# ATmega256RFR2 register map
Vendor: Atmel; File version: 1.0
CPU: other r0p0, little endian, no MPU, no FPU, 4 interrupt priority bits
Registers are 8-bit, read-write, reset 0x0 unless marked. A register's access mark holds for its fields unless they carry their own. Offsets are from the block's base; [hi:lo] are bit positions; {n}, {i} and the like mark numbered series.

## AC — Analog Comparator
Base 0x00000050
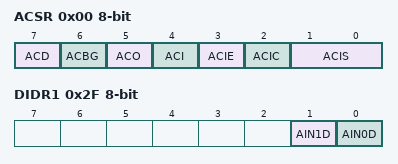
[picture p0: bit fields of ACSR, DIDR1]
0x00 ACSR — Analog Comparator Control And Status Register
  [7] ACD — Analog Comparator Disable
  [6] ACBG — Analog Comparator Bandgap Select
  [5] ACO — Analog Compare Output
  [4] ACI — Analog Comparator Interrupt Flag
  [3] ACIE — Analog Comparator Interrupt Enable
  [2] ACIC — Analog Comparator Input Capture Enable
  [1:0] ACIS — Analog Comparator Interrupt Mode Select
    0=Interrupt on Toggle; 2=Interrupt on Falling Edge; 3=Interrupt on Rising Edge
0x2B ADCSRB — ADC Control and Status Register B
  [6] ACME — Analog Comparator Multiplexer Enable
0x2F DIDR1 — Digital Input Disable Register 1
  [1] AIN1D — AIN1 Digital Input Disable
  [0] AIN0D — AIN0 Digital Input Disable

## ADC — Analog-to-Digital Converter
Base 0x00000077
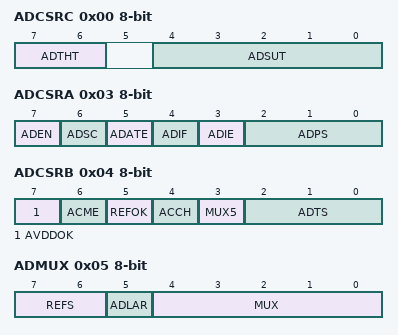
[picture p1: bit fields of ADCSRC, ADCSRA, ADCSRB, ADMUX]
0x00 ADCSRC — The ADC Control and Status Register C
  [7:6] ADTHT — ADC Track-and-Hold Time
    0=Single ended: 1, differential 3 ADC clock cycles; 1=Single ended: 2, differential 5 ADC clock cycles; 2=Single ended: 3, differential 7 ADC clock cycles; 3=Single ended: 4, differential 9 ADC clock cycles
  [4:0] ADSUT — ADC Start-up Time
    0=3 ADC clock cycles; 1=7 ADC clock cycles; 2=11 ADC clock cycles; 3=15 ADC clock cycles; 4=VAL_0x04
0x01 ADC 16-bit (reset mask 0xFF) — ADC Data Register Bytes
0x03 ADCSRA — The ADC Control and Status Register A
  [7] ADEN — ADC Enable
  [6] ADSC — ADC Start Conversion
  [5] ADATE — ADC Auto Trigger Enable
  [4] ADIF — ADC Interrupt Flag
  [3] ADIE — ADC Interrupt Enable
  [2:0] ADPS — ADC Prescaler Select Bits
    0=2; 1=2; 2=4; 3=8; 4=16; 5=32; 6=64; 7=128
0x04 ADCSRB — The ADC Control and Status Register B
  [7] AVDDOK — AVDD Supply Voltage OK
  [6] ACME — Analog Comparator Multiplexer Enable
  [5] REFOK — Reference Voltage OK
  [4] ACCH — Analog Channel Change
  [3] MUX5 — Analog Channel and Gain Selection Bits
  [2:0] ADTS — ADC Auto Trigger Source
    0=Free Running mode; 1=Analog Comparator; 2=External Interrupt Request 0; 3=Timer/Counter0 Compare Match A; 4=Timer/Counter0 Overflow; 5=Timer/Counter1 Compare Match B; 6=Timer/Counter1 Overflow; 7=Timer/Counter1 Capture Event
0x05 ADMUX — The ADC Multiplexer Selection Register
  [7:6] REFS — Reference Selection Bits
    0=AREF, Internal reference voltage generation turned off; 1=AVDD with external capacitor at AREF pin; 2=Internal 1.5V Voltage Reference (no external capacitor at AREF pin); 3=Internal 1.6V Voltage Reference (no external capacitor at AREF pin)
  [5] ADLAR — ADC Left Adjust Result
  [4:0] MUX — Analog Channel and Gain Selection Bits
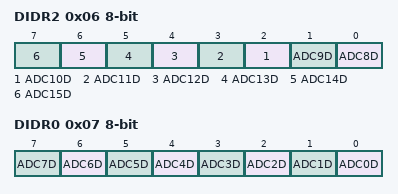
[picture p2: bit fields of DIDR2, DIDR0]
0x06 DIDR2 — Digital Input Disable Register 2
  [n-8] ADC{n}D (n=8..15) — Reserved Bits
0x07 DIDR0 — Digital Input Disable Register 0
  [n] ADC{n}D (n=0..7) — Disable ADC7:0 Digital Input

## BOOT_LOAD — Bootloader
Base 0x00000057
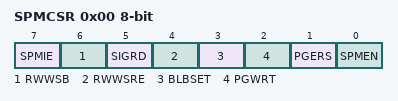
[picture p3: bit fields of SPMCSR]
0x00 SPMCSR — Store Program Memory Control Register
  [7] SPMIE — SPM Interrupt Enable
  [6] RWWSB — Read While Write Section Busy
  [5] SIGRD — Signature Row Read
  [4] RWWSRE — Read While Write Section Read Enable
  [3] BLBSET — Boot Lock Bit Set
  [2] PGWRT — Page Write
  [1] PGERS — Page Erase
  [0] SPMEN — Store Program Memory Enable

## CPU — CPU Registers
Base 0x0000003E
0x00 GPIOR0 — General Purpose IO Register 0
0x0C GPIOR1 — General Purpose IO Register 1
0x0D GPIOR2 — General Purpose I/O Register 2
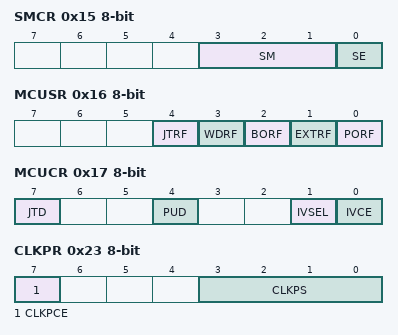
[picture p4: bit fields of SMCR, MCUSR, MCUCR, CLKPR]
0x15 SMCR — Sleep Mode Control Register
  [3:1] SM — Sleep Mode Select bits
    0=IDLE; 1=ADC (ADC Noise Reduction (If Available)); 2=PDOWN (Power Down); 3=PSAVE (Power Save); 6=STDBY (Standby); 7=ESTDBY (Extended Standby)
  [0] SE — Sleep Enable
0x16 MCUSR — MCU Status Register
  [4] JTRF — JTAG Reset Flag
  [3] WDRF — Watchdog Reset Flag
  [2] BORF — Brown-out Reset Flag
  [1] EXTRF — External Reset Flag
  [0] PORF — Power-on Reset Flag
0x17 MCUCR — MCU Control Register
  [7] JTD — JTAG Interface Disable
  [4] PUD — Pull-up Disable
  [1] IVSEL — Interrupt Vector Select
  [0] IVCE — Interrupt Vector Change Enable
0x1D RAMPZ — Extended Z-pointer Register for ELPM/SPM
  [1:0] RAMPZ — Extended Z-Pointer Value
    0=Default value of Z-pointer MSB's
0x1E EIND — Extended Indirect Register
0x23 CLKPR — Clock Prescale Register
  [7] CLKPCE — Clock Prescaler Change Enable
  [3:0] CLKPS — Clock Prescaler Select Bits
    0=Division factor 1 / RC-Oscillator 2; 1=Division factor 2 / RC-Oscillator 4; 2=Division factor 4 / RC-Oscillator 8; 3=Division factor 8 / RC-Oscillator 16; 4=Division factor 16 / RC-Oscillator 32; 5=Division factor 32 / RC-Oscillator 64; 6=Division factor 64 / RC-Oscillator 128; 7=Division factor 128 / RC-Oscillator 256; 8=Division factor 256 / RC-Oscillator 512; 15=Division factor 1 only permitted for RC-Oscillator. Flash and EEPROM programming is not allowed.
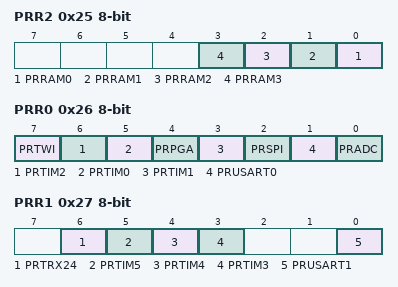
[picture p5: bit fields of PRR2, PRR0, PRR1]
0x25 PRR2 — Power Reduction Register 2
  [n] PRRAM{n} (n=0..3) — Power Reduction SRAM{n}
0x26 PRR0 — Power Reduction Register0
  [7] PRTWI — Power Reduction TWI
  [6] PRTIM2 — Power Reduction Timer/Counter2
  [5] PRTIM0 — Power Reduction Timer/Counter0
  [4] PRPGA — Power Reduction PGA
  [3] PRTIM1 — Power Reduction Timer/Counter1
  [2] PRSPI — Power Reduction Serial Peripheral Interface
  [1] PRUSART0 — Power Reduction USART
  [0] PRADC — Power Reduction ADC
0x27 PRR1 — Power Reduction Register 1
  [6] PRTRX24 — Power Reduction Transceiver
  [5] PRTIM5 — Power Reduction Timer/Counter5
  [4] PRTIM4 — Power Reduction Timer/Counter4
  [3] PRTIM3 — Power Reduction Timer/Counter3
  [0] PRUSART1 — Power Reduction USART1
0x28 OSCCAL — Oscillator Calibration Value
  [7:0] CAL — Oscillator Calibration Tuning Value
    0=Calibration value for lowest oscillator frequency; 127=End value of low frequency range calibration; 128=Start value of high frequency range calibration; 255=Calibration value for highest oscillator frequency
  [7:0] OSCCAL — Oscillator Calibration
